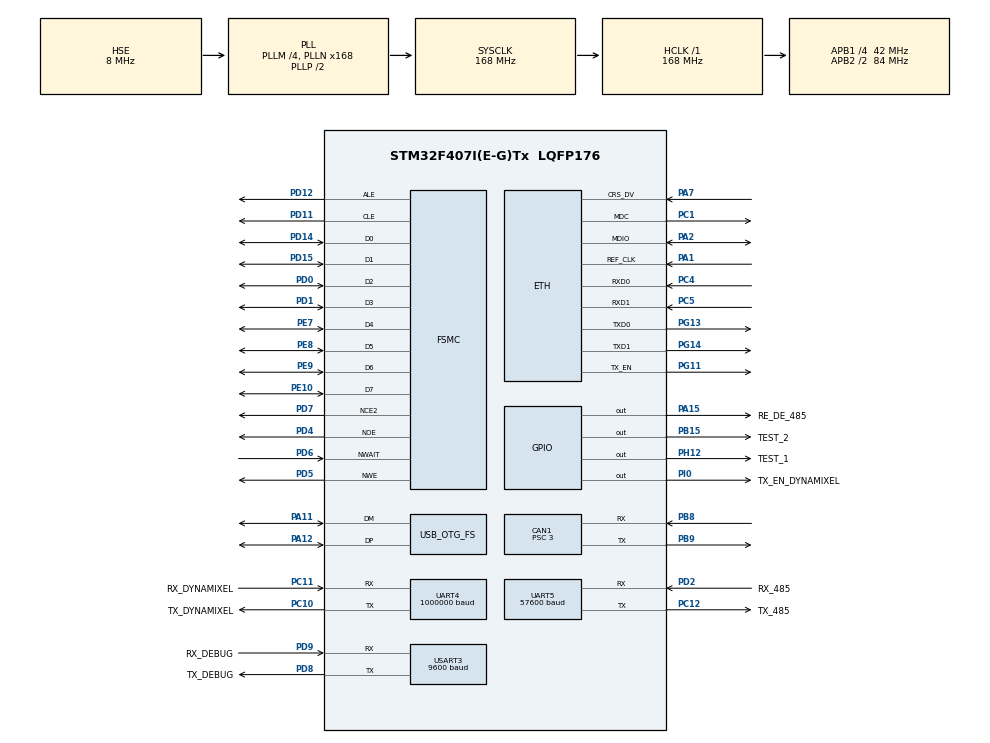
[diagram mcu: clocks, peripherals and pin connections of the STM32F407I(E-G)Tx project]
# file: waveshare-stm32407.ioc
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CAN1.BS1=CAN_BS1_11TQ
CAN1.BS2=CAN_BS2_2TQ
CAN1.CalculateBaudRate=1000000
CAN1.CalculateTimeBit=999.99
CAN1.CalculateTimeQuantum=71.42857142857143
CAN1.Prescaler=3
Dma.Request0=UART4_TX
Dma.Request1=UART4_RX
Dma.Request2=USART3_RX
Dma.Request3=USART3_TX
Dma.Request4=UART5_RX
Dma.Request5=UART5_TX
Dma.UART4_RX.1.Direction=DMA_PERIPH_TO_MEMORY
Dma.UART4_RX.1.FIFOMode=DMA_FIFOMODE_ENABLE
Dma.UART4_RX.1.FIFOThreshold=DMA_FIFO_THRESHOLD_FULL
Dma.UART4_RX.1.Instance=DMA1_Stream2
Dma.UART4_RX.1.MemBurst=DMA_MBURST_SINGLE
Dma.UART4_RX.1.MemDataAlignment=DMA_MDATAALIGN_BYTE
Dma.UART4_RX.1.MemInc=DMA_MINC_ENABLE
Dma.UART4_RX.1.Mode=DMA_NORMAL
Dma.UART4_RX.1.PeriphBurst=DMA_PBURST_SINGLE
Dma.UART4_RX.1.PeriphDataAlignment=DMA_PDATAALIGN_BYTE
Dma.UART4_RX.1.PeriphInc=DMA_PINC_DISABLE
Dma.UART4_RX.1.Priority=DMA_PRIORITY_HIGH
Dma.UART4_TX.0.Direction=DMA_MEMORY_TO_PERIPH
Dma.UART4_TX.0.FIFOMode=DMA_FIFOMODE_DISABLE
Dma.UART4_TX.0.Instance=DMA1_Stream4
Dma.UART4_TX.0.MemDataAlignment=DMA_MDATAALIGN_BYTE
Dma.UART4_TX.0.MemInc=DMA_MINC_ENABLE
Dma.UART4_TX.0.Mode=DMA_NORMAL
Dma.UART4_TX.0.PeriphDataAlignment=DMA_PDATAALIGN_BYTE
Dma.UART4_TX.0.PeriphInc=DMA_PINC_DISABLE
Dma.UART4_TX.0.Priority=DMA_PRIORITY_HIGH
Dma.UART5_RX.4.Direction=DMA_PERIPH_TO_MEMORY
Dma.UART5_RX.4.FIFOMode=DMA_FIFOMODE_DISABLE
Dma.UART5_RX.4.Instance=DMA1_Stream0
Dma.UART5_RX.4.MemDataAlignment=DMA_MDATAALIGN_BYTE
Dma.UART5_RX.4.MemInc=DMA_MINC_ENABLE
Dma.UART5_RX.4.Mode=DMA_NORMAL
Dma.UART5_RX.4.PeriphDataAlignment=DMA_PDATAALIGN_BYTE
Dma.UART5_RX.4.PeriphInc=DMA_PINC_DISABLE
Dma.UART5_RX.4.Priority=DMA_PRIORITY_HIGH
Dma.UART5_TX.5.Direction=DMA_MEMORY_TO_PERIPH
Dma.UART5_TX.5.FIFOMode=DMA_FIFOMODE_DISABLE
Dma.UART5_TX.5.Instance=DMA1_Stream7
Dma.UART5_TX.5.MemDataAlignment=DMA_MDATAALIGN_BYTE
Dma.UART5_TX.5.MemInc=DMA_MINC_ENABLE
Dma.UART5_TX.5.Mode=DMA_NORMAL
Dma.UART5_TX.5.PeriphDataAlignment=DMA_PDATAALIGN_BYTE
Dma.UART5_TX.5.PeriphInc=DMA_PINC_DISABLE
Dma.UART5_TX.5.Priority=DMA_PRIORITY_HIGH
Dma.USART3_RX.2.Direction=DMA_PERIPH_TO_MEMORY
Dma.USART3_RX.2.FIFOMode=DMA_FIFOMODE_ENABLE
Dma.USART3_RX.2.FIFOThreshold=DMA_FIFO_THRESHOLD_FULL
Dma.USART3_RX.2.Instance=DMA1_Stream1
Dma.USART3_RX.2.MemBurst=DMA_MBURST_SINGLE
Dma.USART3_RX.2.MemDataAlignment=DMA_MDATAALIGN_BYTE
Dma.USART3_RX.2.MemInc=DMA_MINC_ENABLE
Dma.USART3_RX.2.Mode=DMA_NORMAL
Dma.USART3_RX.2.PeriphBurst=DMA_PBURST_SINGLE
Dma.USART3_RX.2.PeriphDataAlignment=DMA_PDATAALIGN_BYTE
Dma.USART3_RX.2.PeriphInc=DMA_PINC_DISABLE
Dma.USART3_RX.2.Priority=DMA_PRIORITY_LOW
Dma.USART3_TX.3.Direction=DMA_MEMORY_TO_PERIPH
Dma.USART3_TX.3.FIFOMode=DMA_FIFOMODE_ENABLE
Dma.USART3_TX.3.FIFOThreshold=DMA_FIFO_THRESHOLD_FULL
Dma.USART3_TX.3.Instance=DMA1_Stream3
Dma.USART3_TX.3.MemBurst=DMA_MBURST_SINGLE
Dma.USART3_TX.3.MemDataAlignment=DMA_MDATAALIGN_BYTE
Dma.USART3_TX.3.MemInc=DMA_MINC_ENABLE
Dma.USART3_TX.3.Mode=DMA_NORMAL
Dma.USART3_TX.3.PeriphBurst=DMA_PBURST_SINGLE
Dma.USART3_TX.3.PeriphDataAlignment=DMA_PDATAALIGN_BYTE
Dma.USART3_TX.3.PeriphInc=DMA_PINC_DISABLE
Dma.USART3_TX.3.Priority=DMA_PRIORITY_LOW
ETH.MACAddr=00\:80\:E1\:E2\:E3\:E4
ETH.MediaInterface=ETH_MEDIA_INTERFACE_RMII
ETH.PHY_ISFR=0x000B
FATFS._CODE_PAGE=855
FATFS._MAX_SS=2048
FATFS._MIN_SS=2048
FATFS._USE_LFN=1
FSMC.AttributeSpaceHiZSetupTime1=1
FSMC.AttributeSpaceHoldSetupTime1=3
FSMC.AttributeSpaceSetupTime1=0
FSMC.AttributeSpaceWaitSetupTime1=2
FSMC.CommonSpaceHiZSetupTime1=1
FSMC.CommonSpaceHoldSetupTime1=3
FSMC.CommonSpaceSetupTime1=0
FSMC.CommonSpaceWaitSetupTime1=2
FSMC.ECCPageSize1=FSMC_NAND_ECC_PAGE_SIZE_2048BYTE
FSMC.EccComputation1=FSMC_NAND_ECC_ENABLE
FSMC.NandBlockNbr1=NAND0_BLOCK_NUMBER
FSMC.NandBlockSize1=NAND0_BLOCK_SIZE
FSMC.NandPageSize1=NAND0_PAGE_SIZE
FSMC.NandPlaneNbr1=NAND0_PLAN_NUMBER
FSMC.NandPlaneSize1=NAND0_PLAN_SIZE
FSMC.NandSpareAreaSize1=NAND0_SPARE_AREA_SIZE
LWIP.DHCP_DEBUG=LWIP_DBG_ON
LWIP.GATEWAY_ADDRESS=192.168.001.001
LWIP.IP_ADDRESS=192.168.001.034
LWIP.LWIP_DHCP=0
LWIP.LWIP_ICMP=1
LWIP.LWIP_TCP=1
LWIP.LWIP_TFTP=1
LWIP.LWIP_UDP=1
LWIP.NETMASK_ADDRESS=255.255.255.000
LWIP.TFTP_DEBUG=LWIP_DBG_ON
LWIP.TFTP_MAX_FILENAME_LEN=255
LWIP.Version=v2.1.2_Cube
Mcu.Family=STM32F4
Mcu.Name=STM32F407I(E-G)Tx
Mcu.Package=LQFP176
Mcu.UserConstants=NAND0_PAGE_SIZE,0x800;NAND0_SPARE_AREA_SIZE,0x40;NAND0_BLOCK_SIZE,0x40;NAND0_BLOCK_NUMBER,0x400;NAND0_PLAN_SIZE,0x400;NAND0_PLAN_NUMBER,1
NVIC.CAN1_RX0_IRQn=true\:1\:0\:true\:false\:true\:true\:true
NVIC.CAN1_SCE_IRQn=true\:4\:0\:true\:false\:true\:true\:true
NVIC.CAN1_TX_IRQn=true\:1\:0\:true\:false\:true\:true\:true
NVIC.DMA1_Stream0_IRQn=true\:1\:0\:true\:false\:true\:false\:true
NVIC.DMA1_Stream1_IRQn=true\:4\:0\:true\:false\:true\:false\:true
NVIC.DMA1_Stream2_IRQn=true\:1\:0\:true\:false\:true\:false\:true
NVIC.DMA1_Stream3_IRQn=true\:4\:0\:true\:false\:true\:false\:true
NVIC.DMA1_Stream4_IRQn=true\:1\:0\:true\:false\:true\:false\:true
NVIC.DMA1_Stream7_IRQn=true\:1\:0\:true\:false\:true\:false\:true
NVIC.ETH_IRQn=true\:4\:0\:true\:false\:true\:true\:true
NVIC.OTG_FS_IRQn=true\:4\:0\:true\:false\:true\:false\:true
NVIC.PriorityGroup=NVIC_PRIORITYGROUP_4
NVIC.TIM7_IRQn=true\:3\:0\:true\:false\:true\:true\:true
NVIC.UART4_IRQn=true\:2\:0\:true\:false\:true\:true\:true
NVIC.UART5_IRQn=true\:2\:0\:true\:false\:true\:true\:true
NVIC.USART3_IRQn=true\:4\:0\:true\:false\:true\:true\:true
PA1.Mode=RMII
PA1.Signal=ETH_REF_CLK
PA11.Mode=Device_Only
PA11.Signal=USB_OTG_FS_DM
PA12.Mode=Device_Only
PA12.Signal=USB_OTG_FS_DP
PA13.GPIO_Label=SWDIO
PA13.Mode=Serial_Wire
PA13.Signal=SYS_JTMS-SWDIO
PA14.GPIO_Label=SWCLK
PA14.Mode=Serial_Wire
PA14.Signal=SYS_JTCK-SWCLK
PA15.GPIO_Label=RE_DE_485
PA15.Signal=GPIO_Output
PA2.Mode=RMII
PA2.Signal=ETH_MDIO
PA7.Mode=RMII
PA7.Signal=ETH_CRS_DV
PB12.Signal=CAN2_RX
PB13.Signal=CAN2_TX
PB15.GPIO_Label=TEST_2
PB15.Signal=GPIO_Output
PB8.Mode=CAN_Activate
PB8.Signal=CAN1_RX
PB9.Mode=CAN_Activate
PB9.Signal=CAN1_TX
PC1.Mode=RMII
PC1.Signal=ETH_MDC
PC10.GPIO_Label=TX_DYNAMIXEL
PC10.Mode=Asynchronous
PC10.Signal=UART4_TX
PC11.GPIO_Label=RX_DYNAMIXEL
PC11.Mode=Asynchronous
PC11.Signal=UART4_RX
PC12.GPIO_Label=TX_485
PC12.Mode=Asynchronous
PC12.Signal=UART5_TX
PC4.Mode=RMII
PC4.Signal=ETH_RXD0
PC5.Mode=RMII
PC5.Signal=ETH_RXD1
PD0.Signal=FSMC_D2_DA2
PD1.Signal=FSMC_D3_DA3
PD11.Signal=FSMC_A16_CLE
PD12.Signal=FSMC_A17_ALE
PD14.Signal=FSMC_D0_DA0
PD15.Signal=FSMC_D1_DA1
PD2.GPIO_Label=RX_485
PD2.Mode=Asynchronous
PD2.Signal=UART5_RX
PD4.Signal=FSMC_NOE
PD5.Signal=FSMC_NWE
PD6.Signal=FSMC_NWAIT
PD7.Mode=NandChipSelect2_1
PD7.Signal=FSMC_NCE2
PD8.GPIO_Label=TX_DEBUG
PD8.Mode=Asynchronous
PD8.Signal=USART3_TX
PD9.GPIO_Label=RX_DEBUG
PD9.Mode=Asynchronous
PD9.Signal=USART3_RX
PE10.Signal=FSMC_D7_DA7
PE7.Signal=FSMC_D4_DA4
PE8.Signal=FSMC_D5_DA5
PE9.Signal=FSMC_D6_DA6
PG11.Mode=RMII
PG11.Signal=ETH_TX_EN
PG13.Mode=RMII
PG13.Signal=ETH_TXD0
PG14.Mode=RMII
PG14.Signal=ETH_TXD1
PH0-OSC_IN.Mode=HSE-External-Oscillator
PH0-OSC_IN.Signal=RCC_OSC_IN
PH1-OSC_OUT.Mode=HSE-External-Oscillator
PH1-OSC_OUT.Signal=RCC_OSC_OUT
PH12.GPIO_Label=TEST_1
PH12.Signal=GPIO_Output
PI0.GPIO_Label=TX_EN_DYNAMIXEL
PI0.GPIO_Speed=GPIO_SPEED_FREQ_VERY_HIGH
PI0.Signal=GPIO_Output
ProjectManager.HeapSize=0x4000
ProjectManager.StackSize=0x400
ProjectManager.TargetToolchain=MDK-ARM V5.27
RCC.48MHZClocksFreq_Value=48000000
RCC.AHBFreq_Value=168000000
RCC.APB1CLKDivider=RCC_HCLK_DIV4
RCC.APB1Freq_Value=42000000
RCC.APB1TimFreq_Value=84000000
RCC.APB2CLKDivider=RCC_HCLK_DIV2
RCC.APB2Freq_Value=84000000
RCC.APB2TimFreq_Value=168000000
RCC.CortexFreq_Value=168000000
RCC.HCLKFreq_Value=168000000
RCC.HSE_VALUE=8000000
RCC.HSI_VALUE=16000000
RCC.LSE_VALUE=32768
RCC.PLLM=4
RCC.PLLN=168
RCC.PLLQ=7
RCC.SYSCLKFreq_VALUE=168000000
RCC.SYSCLKSource=RCC_SYSCLKSOURCE_PLLCLK
RCC.VCOOutputFreq_Value=336000000
SH.FSMC_A16_CLE.0=FSMC_CLE,8b-dmux1
SH.FSMC_A17_ALE.0=FSMC_ALE,8b-dmux1
SH.FSMC_D0_DA0.0=FSMC_D0,8b-dmux1
SH.FSMC_D1_DA1.0=FSMC_D1,8b-dmux1
SH.FSMC_D2_DA2.0=FSMC_D2,8b-dmux1
SH.FSMC_D3_DA3.0=FSMC_D3,8b-dmux1
SH.FSMC_D4_DA4.0=FSMC_D4,8b-dmux1
SH.FSMC_D5_DA5.0=FSMC_D5,8b-dmux1
SH.FSMC_D6_DA6.0=FSMC_D6,8b-dmux1
SH.FSMC_D7_DA7.0=FSMC_D7,8b-dmux1
SH.FSMC_NOE.0=FSMC_NOE,8b-dmux1
SH.FSMC_NWAIT.0=FSMC_NWAIT,Wait1
SH.FSMC_NWE.0=FSMC_NWE,8b-dmux1
TIM1.Channel-Output\ Compare1\ No\ Output=TIM_CHANNEL_1
TIM7.Period=1000
TIM7.Prescaler=84
UART4.BaudRate=1000000
UART4.VirtualMode=Asynchronous
UART5.BaudRate=57600
UART5.VirtualMode=Asynchronous
USART3.BaudRate=9600
USART3.VirtualMode=VM_ASYNC
USB_DEVICE.CLASS_NAME_FS=CDC
USB_DEVICE.VirtualMode-CDC_FS=Cdc
USB_DEVICE.VirtualModeFS=Cdc_FS
USB_OTG_FS.VirtualMode=Device_Only
VP_FATFS_VS_Generic.Mode=User_defined
VP_LWIP_VS_Enabled.Mode=Enabled
VP_TIM1_VS_no_output1.Mode=Output Compare1 No Output
VP_TIM7_VS_ClockSourceINT.Mode=Enable_Timer
VP_USB_DEVICE_VS_USB_DEVICE_CDC_FS.Mode=CDC_FS
board=custom

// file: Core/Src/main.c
/* USER CODE BEGIN Header */
/**
  ******************************************************************************
  * @file           : main.c
  * @brief          : Main program body
  ******************************************************************************
  * @attention
  *
  * <h2><center>&copy; Copyright (c) 2021 STMicroelectronics.
  * All rights reserved.</center></h2>
  *
  * This software component is licensed by ST under BSD 3-Clause license,
  * the "License"; You may not use this file except in compliance with the
  * License. You may obtain a copy of the License at:
  *                        opensource.org/licenses/BSD-3-Clause
  *
  ******************************************************************************
  */
/* USER CODE END Header */
#include "main.h"
#include "can.h"
#include "dma.h"
#include "fatfs.h"
#include "lwip.h"
#include "tim.h"
#include "usart.h"
#include "usb_device.h"
#include "gpio.h"
#include "fsmc.h"

/* USER CODE BEGIN Includes */
#include "avatar-central-common.h"
#include "usbd_cdc_if.h"
/* USER CODE END Includes */

void SystemClock_Config(void);

int main(void)
{
  /* USER CODE BEGIN 1 */
	/*if( RCC->CSR & RCC_CSR_IWDGRSTF){
		RCC->CSR &= ~RCC_CSR_IWDGRSTF;
	}*/
  /* USER CODE END 1 */

  /* MCU Configuration--------------------------------------------------------*/

  /* Reset of all peripherals, Initializes the Flash interface and the Systick. */
  HAL_Init();

  /* Configure the system clock */
  SystemClock_Config();

  /* Initialize all configured peripherals */
  MX_GPIO_Init();
  MX_DMA_Init();
  MX_FSMC_Init();
  MX_FATFS_Init();
  MX_UART4_Init();
  MX_LWIP_Init();
  MX_USB_DEVICE_Init();
  MX_CAN1_Init();
  MX_USART3_UART_Init();
  MX_UART5_Init();
  MX_TIM1_Init();
  MX_TIM7_Init();

  /* USER CODE BEGIN 2 */
	//while(!usb_rx_flag);
	if ( avatar_central_begin() !=0 ) avatar_central_finish();
  /* USER CODE END 2 */

  /* Infinite loop */
  /* USER CODE BEGIN WHILE */
  while (1)
  {
	avatar_central_loop();
    /* USER CODE END WHILE */

  }
}

void SystemClock_Config(void)
{
  RCC_OscInitTypeDef RCC_OscInitStruct = {0};
  RCC_ClkInitTypeDef RCC_ClkInitStruct = {0};

  /** Configure the main internal regulator output voltage
  */
  __HAL_RCC_PWR_CLK_ENABLE();
  __HAL_PWR_VOLTAGESCALING_CONFIG(PWR_REGULATOR_VOLTAGE_SCALE1);
  /** Initializes the RCC Oscillators according to the specified parameters
  * in the RCC_OscInitTypeDef structure.
  */
  RCC_OscInitStruct.OscillatorType = RCC_OSCILLATORTYPE_HSE;
  RCC_OscInitStruct.HSEState = RCC_HSE_ON;
  RCC_OscInitStruct.PLL.PLLState = RCC_PLL_ON;
  RCC_OscInitStruct.PLL.PLLSource = RCC_PLLSOURCE_HSE;
  RCC_OscInitStruct.PLL.PLLM = 4;
  RCC_OscInitStruct.PLL.PLLN = 168;
  RCC_OscInitStruct.PLL.PLLP = RCC_PLLP_DIV2;
  RCC_OscInitStruct.PLL.PLLQ = 7;
  if (HAL_RCC_OscConfig(&RCC_OscInitStruct) != HAL_OK)
  {
    Error_Handler();
  }
  /** Initializes the CPU, AHB and APB buses clocks
  */
  RCC_ClkInitStruct.ClockType = RCC_CLOCKTYPE_HCLK|RCC_CLOCKTYPE_SYSCLK
                              |RCC_CLOCKTYPE_PCLK1|RCC_CLOCKTYPE_PCLK2;
  RCC_ClkInitStruct.SYSCLKSource = RCC_SYSCLKSOURCE_PLLCLK;
  RCC_ClkInitStruct.AHBCLKDivider = RCC_SYSCLK_DIV1;
  RCC_ClkInitStruct.APB1CLKDivider = RCC_HCLK_DIV4;
  RCC_ClkInitStruct.APB2CLKDivider = RCC_HCLK_DIV2;

  if (HAL_RCC_ClockConfig(&RCC_ClkInitStruct, FLASH_LATENCY_5) != HAL_OK)
  {
    Error_Handler();
  }
}

void Error_Handler(void)
{
  __disable_irq();
  while (1)
  {
  }
}

/************************ (C) COPYRIGHT STMicroelectronics *****END OF FILE****/
